# STM32G554 register map
File version: 2.0.0
CPU: CM33 r0p4, little endian, MPU, FPU, 4 interrupt priority bits
Registers are 32-bit, read-write, reset 0x0 unless marked. A register's access mark holds for its fields unless they carry their own. Offsets are from the block's base; [hi:lo] are bit positions.

## FMAC1 — FMAC register block
Base 0x40023C00
Same registers: FMAC2 0x42024400, FMAC1_S 0x50023C00, FMAC2_S 0x52024400
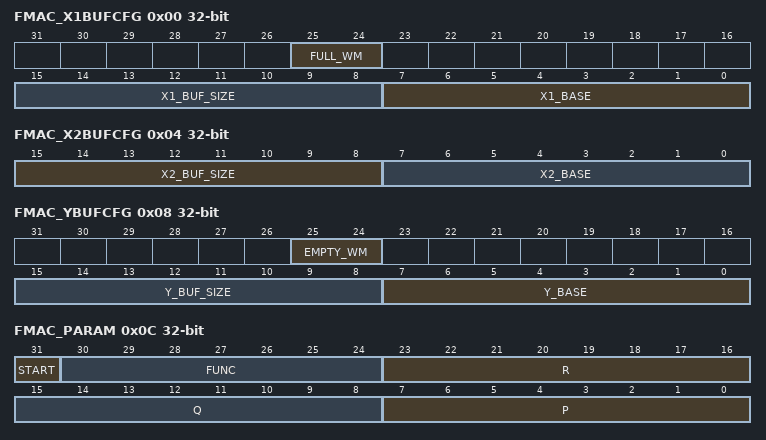
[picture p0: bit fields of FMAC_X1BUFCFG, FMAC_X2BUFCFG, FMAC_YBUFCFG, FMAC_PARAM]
0x00 FMAC_X1BUFCFG — FMAC X1 buffer configuration register
  [25:24] FULL_WM — Watermark for buffer full flag
    0=Threshold = 1; 1=Threshold = 2
  [15:8] X1_BUF_SIZE — Allocated size of X1 buffer in 16-bit words
  [7:0] X1_BASE — Base address of X1 buffer
0x04 FMAC_X2BUFCFG — FMAC X2 buffer configuration register
  [15:8] X2_BUF_SIZE — Size of X2 buffer in 16-bit words
  [7:0] X2_BASE — Base address of X2 buffer
0x08 FMAC_YBUFCFG — FMAC Y buffer configuration register
  [25:24] EMPTY_WM — Watermark for buffer empty flag
    0=Threshold = 1; 1=Threshold = 2
  [15:8] Y_BUF_SIZE — Size of Y buffer in 16-bit words
  [7:0] Y_BASE — Base address of Y buffer
0x0C FMAC_PARAM — FMAC parameter register
  [31] START — Enable execution
    0=Stop execution; 1=Start execution
  [30:24] FUNC — Function
    1=Load X1 buffer
  [23:16] R — Input parameter R.
  [15:8] Q — Input parameter Q.
  [7:0] P — Input parameter P.
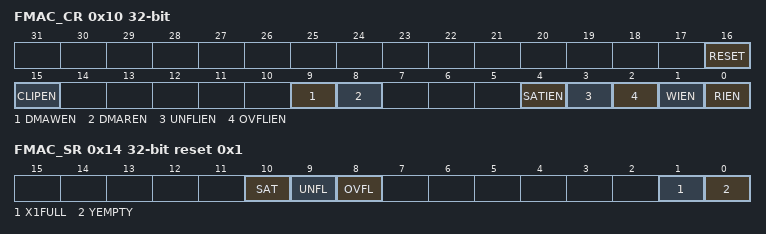
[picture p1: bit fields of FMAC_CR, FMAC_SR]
0x10 FMAC_CR — FMAC control register
  [16] RESET — Reset FMAC unit
    0=Reset inactive; 1=Reset active
  [15] CLIPEN — Enable clipping
    0=Clipping disabled. Values at the output of the accumulator which exceed the q1.15 range, wrap.; 1=Clipping enabled. Values at the output of the accumulator which exceed the q1.15 range are saturated to the maximum positive or negative value (+1 or -1) according to the sign.
  [9] DMAWEN — Enable DMA write channel requests
    0=Disable. No DMA requests are generated; 1=Enable. DMA requests are generated while the X1 buffer is not full.
  [8] DMAREN — Enable DMA read channel requests
    0=Disable. No DMA requests are generated; 1=Enable. DMA requests are generated while the Y buffer is not empty.
  [4] SATIEN — Enable saturation error interrupts
    0=Disabled. No interrupts are generated upon saturation detection.; 1=Enabled. An interrupt request is generated if the SAT flag is set
  [3] UNFLIEN — Enable underflow error interrupts
    0=Disabled. No interrupts are generated upon underflow detection.; 1=Enabled. An interrupt request is generated if the UNFL flag is set
  [2] OVFLIEN — Enable overflow error interrupts
    0=Disabled. No interrupts are generated upon overflow detection.; 1=Enabled. An interrupt request is generated if the OVFL flag is set
  [1] WIEN — Enable write interrupt
    0=Disabled. No write interrupt requests are generated.; 1=Enabled. An interrupt request is generated while the X1 buffer FULL flag is not set.
  [0] RIEN — Enable read interrupt
    0=Disabled. No read interrupt requests are generated.; 1=Enabled. An interrupt request is generated while the Y buffer EMPTY flag is not set.
0x14 FMAC_SR ro reset 0x1 — FMAC status register
  [10] SAT — Saturation error flag
    0=No saturation detected; 1=Saturation detected. If the SATIEN bit is set, an interrupt is generated.
  [9] UNFL — Underflow error flag
    0=No underflow detected; 1=Underflow detected. If the UNFLIEN bit is set, an interrupt is generated.
  [8] OVFL — Overflow error flag
    0=No overflow detected; 1=Overflow detected. If the OVFLIEN bit is set, an interrupt is generated.
  [1] X1FULL — X1 buffer full flag
    0=X1 buffer not full. If the WIEN bit is set, the interrupt request is asserted until the flag is set. If DMAWEN is set, DMA write channel requests are generated until the flag is set.; 1=X1 buffer full
  [0] YEMPTY — Y buffer empty flag
    0=Y buffer not empty. If the RIEN bit is set, the interrupt request is asserted until the flag is set. If DMAREN is set, DMA read channel requests are generated until the flag is set.; 1=Y buffer empty
0x18 FMAC_WDATA wo — FMAC write data register
  [15:0] WDATA — Write data
0x1C FMAC_RDATA ro — FMAC read data register
  [15:0] RDATA — Read data
